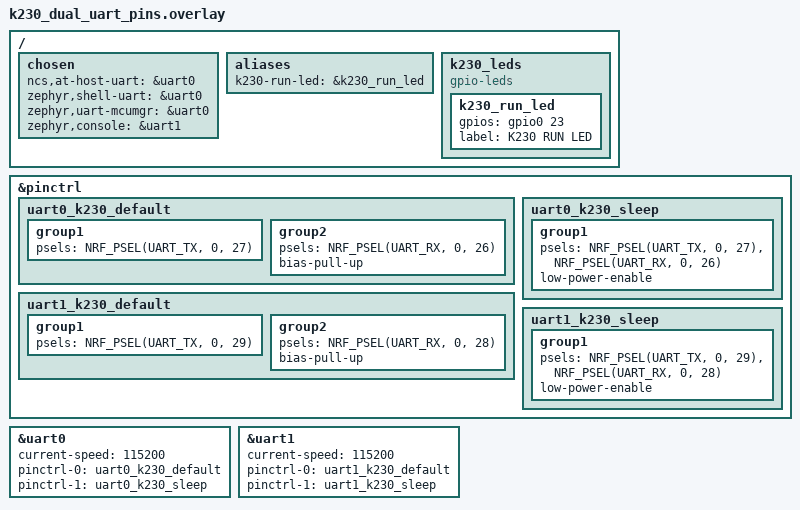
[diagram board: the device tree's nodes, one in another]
/*
 * K230 <-> nRF9151 dual-UART overlay.
 *
 * User hardware naming:
 * - nRF9151 UART1: TX1=P0.27, RX1=P0.26, 115200 8N1, no RTS/CTS.
 * - nRF9151 UART2: TX2=P0.29, RX2=P0.28, 115200 8N1, no RTS/CTS.
 * - RUN LED: P0.23, active high.
 *
 * Zephyr node mapping:
 * - uart0 = user UART1 = AT command link to K230.
 * - uart1 = user UART2 = printk/log output.
 */

#include <zephyr/dt-bindings/gpio/gpio.h>
#include <zephyr/dt-bindings/pinctrl/nrf-pinctrl.h>

/ {
	chosen {
		ncs,at-host-uart = &uart0;
		zephyr,shell-uart = &uart0;
		zephyr,uart-mcumgr = &uart0;
		zephyr,console = &uart1;
	};

	aliases {
		k230-run-led = &k230_run_led;
	};

	k230_leds {
		compatible = "gpio-leds";

		k230_run_led: k230_run_led {
			gpios = <&gpio0 23 GPIO_ACTIVE_HIGH>;
			label = "K230 RUN LED";
		};
	};

};

&pinctrl {
	uart0_k230_default: uart0_k230_default {
		group1 {
			psels = <NRF_PSEL(UART_TX, 0, 27)>;
		};

		group2 {
			psels = <NRF_PSEL(UART_RX, 0, 26)>;
			bias-pull-up;
		};
	};

	uart0_k230_sleep: uart0_k230_sleep {
		group1 {
			psels = <NRF_PSEL(UART_TX, 0, 27)>,
				<NRF_PSEL(UART_RX, 0, 26)>;
			low-power-enable;
		};
	};

	uart1_k230_default: uart1_k230_default {
		group1 {
			psels = <NRF_PSEL(UART_TX, 0, 29)>;
		};

		group2 {
			psels = <NRF_PSEL(UART_RX, 0, 28)>;
			bias-pull-up;
		};
	};

	uart1_k230_sleep: uart1_k230_sleep {
		group1 {
			psels = <NRF_PSEL(UART_TX, 0, 29)>,
				<NRF_PSEL(UART_RX, 0, 28)>;
			low-power-enable;
		};
	};
};

&uart0 {
	status = "okay";
	current-speed = <115200>;
	pinctrl-0 = <&uart0_k230_default>;
	pinctrl-1 = <&uart0_k230_sleep>;
	pinctrl-names = "default", "sleep";
	/delete-property/ hw-flow-control;
};

&uart1 {
	status = "okay";
	current-speed = <115200>;
	pinctrl-0 = <&uart1_k230_default>;
	pinctrl-1 = <&uart1_k230_sleep>;
	pinctrl-names = "default", "sleep";
	/delete-property/ hw-flow-control;
};
